# STM32G071 register map
File version: 2.1
CPU: CM0 r0p1, little endian, MPU, no FPU, 4 interrupt priority bits
Registers are 32-bit, read-write, reset 0x0 unless marked. A register's access mark holds for its fields unless they carry their own. Offsets are from the block's base; [hi:lo] are bit positions; {n}, {i} and the like mark numbered series; 'fields as' and 'values as' point back to an identical list.

## TIM15 — General purpose timers
Base 0x40014000
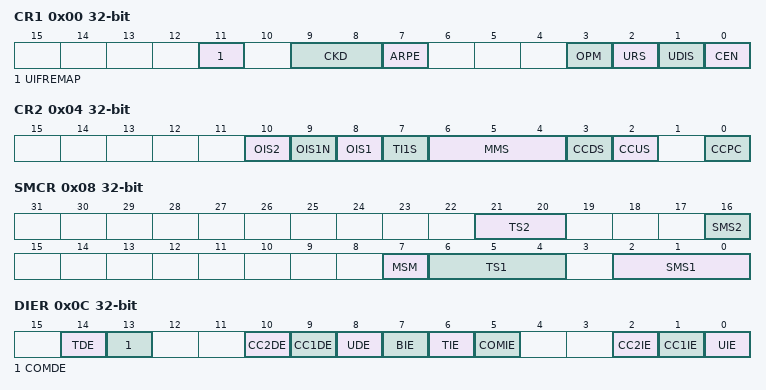
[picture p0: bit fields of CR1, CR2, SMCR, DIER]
0x00 CR1 — control register 1
  [11] UIFREMAP — UIF status bit remapping
    0=No remapping. UIF status bit is not copied to TIMx_CNT register bit 31.; 1=Remapping enabled. UIF status bit is copied to TIMx_CNT register bit 31.
  [9:8] CKD — Clock division This bitfield indicates the division ratio between the timer clock (CK_INT) frequency and the dead-time and sampling clock (tDTS) used by the dead-time generators and the digital filters (TIx)
    0=tDTS = tCK_INT; 1=tDTS = 2*tCK_INT; 2=tDTS = 4*tCK_INT; 3=Reserved, do not program this value
  [7] ARPE — Auto-reload preload enable
    0=TIMx_ARR register is not buffered; 1=TIMx_ARR register is buffered
  [3] OPM — One-pulse mode
    0=Counter is not stopped at update event; 1=Counter stops counting at the next update event (clearing the bit CEN)
  [2] URS — Update request source This bit is set and cleared by software to select the UEV event sources. Counter overflow/underflow Setting the UG bit Update generation through the slave mode controller
    0=Any of the following events generate an update interrupt if enabled. These events can be:; 1=Only counter overflow/underflow generates an update interrupt if enabled
  [1] UDIS — Update disable This bit is set and cleared by software to enable/disable UEV event generation. Counter overflow/underflow Setting the UG bit Update generation through the slave mode controller Buffered registers are then loaded with their preload values.
    0=UEV enabled. The Update (UEV) event is generated by one of the following events:; 1=UEV disabled. The Update event is not generated, shadow registers keep their value (ARR, PSC, CCRx). However the counter and the prescaler are reinitialized if the UG bit is set or if a hardware reset is received from the slave mode controller.
  [0] CEN — Counter enable Note: External clock and gated mode can work only if the CEN bit has been previously set by software. However trigger mode can set the CEN bit automatically by hardware.
    0=Counter disabled; 1=Counter enabled
0x04 CR2 — control register 2
  [10] OIS2 — Output idle state 2 (OC2 output) Note: This bit cannot be modified as long as LOCK level 1, 2 or 3 has been programmed (LOCK bits in the TIM15_BDTR register).
    0=OC2=0 when MOE=0; 1=OC2=1 when MOE=0
  [9] OIS1N — Output Idle state 1 (OC1N output) Note: This bit can not be modified as long as LOCK level 1, 2 or 3 has been programmed (LOCK bits in TIM15_BDTR register).
    0=OC1N=0 after a dead-time when MOE=0; 1=OC1N=1 after a dead-time when MOE=0
  [8] OIS1 — Output Idle state 1 (OC1 output) Note: This bit can not be modified as long as LOCK level 1, 2 or 3 has been programmed (LOCK bits in TIM15_BDTR register).
    0=OC1=0 (after a dead-time if OC1N is implemented) when MOE=0; 1=OC1=1 (after a dead-time if OC1N is implemented) when MOE=0
  [7] TI1S — TI1 selection
    0=The TIMx_CH1 pin is connected to TI1 input; 1=The TIMx_CH1, CH2 pins are connected to the TI1 input (XOR combination)
  [6:4] MMS — Master mode selection These bits allow to select the information to be sent in master mode to slave timers for synchronization (TRGO). The combination is as follows:
    0=Reset - the UG bit from the TIMx_EGR register is used as trigger output (TRGO). If the reset is generated by the trigger input (slave mode controller configured in reset mode) then the signal on TRGO is delayed compared to the actual reset.; 1=Enable - the Counter Enable signal CNT_EN is used as trigger output (TRGO). It is useful to start several timers at the same time or to control a window in which a slave timer is enable. The Counter Enable signal is generated by a logic AND between CEN control bit and the trigger input when configured in gated mode. When the Counter Enable signal is controlled by the trigger input, there is a delay on TRGO, except if the master/slave mode is selected (see the MSM bit description in TIMx_SMCR register).; 2=Update - The update event is selected as trigger output (TRGO). For instance a master timer can then be used as a prescaler for a slave timer.; 3=Compare Pulse - The trigger output send a positive pulse when the CC1IF flag is to be set (even if it was already high), as soon as a capture or a compare match occurred. (TRGO).; 4=Compare - OC1REFC signal is used as trigger output (TRGO); 5=Compare - OC2REFC signal is used as trigger output (TRGO)
  [3] CCDS — Capture/compare DMA selection
    0=CCx DMA request sent when CCx event occurs; 1=CCx DMA requests sent when update event occurs
  [2] CCUS — Capture/compare control update selection Note: This bit acts only on channels that have a complementary output.
    0=When capture/compare control bits are preloaded (CCPC=1), they are updated by setting the COMG bit only; 1=When capture/compare control bits are preloaded (CCPC=1), they are updated by setting the COMG bit or when an rising edge occurs on TRGI
  [0] CCPC — Capture/compare preloaded control Note: This bit acts only on channels that have a complementary output.
    0=CCxE, CCxNE and OCxM bits are not preloaded; 1=CCxE, CCxNE and OCxM bits are preloaded, after having been written, they are updated only when a commutation event (COM) occurs (COMG bit set or rising edge detected on TRGI, depending on the CCUS bit)
0x08 SMCR — slave mode control register
  [21:20] TS2 — Trigger selection This bit field selects the trigger input to be used to synchronize the counter. Other: Reserved See for more details on ITRx meaning for each Timer. Note: These bits must be changed only when they are not used (e.g. when SMS=000) to avoid wrong edge detections at the transition.
    {v}=Internal Trigger {v} (ITR{v}) (v=0..3); 4=TI1 Edge Detector (TI1F_ED); 5=Filtered Timer Input 1 (TI1FP1); 6=Filtered Timer Input 2 (TI2FP2)
  [16] SMS2 — Slave mode selection When external signals are selected the active edge of the trigger signal (TRGI) is linked to the polarity selected on the external input (see Input Control register and Control Register description. Other codes: reserved. Note: The gated mode must not be used if TI1F_ED is selected as the trigger input (TS='00100'). Indeed, TI1F_ED outputs 1 pulse for each transition on TI1F, whereas the gated mode checks the level of the trigger signal. Note: The clock of the slave peripherals (timer, ADC, ...) receiving the TRGO or the TRGO2 signals must be enabled prior to receive events from the master timer, and the clock frequency (prescaler) must not be changed on-the-fly while triggers are received from the master timer.
    0=Slave mode disabled - if CEN = '1' then the prescaler is clocked directly by the internal clock; 4=Reset Mode - Rising edge of the selected trigger input (TRGI) reinitializes the counter and generates an update of the registers; 5=Gated Mode - The counter clock is enabled when the trigger input (TRGI) is high. The counter stops (but is not reset) as soon as the trigger becomes low. Both start and stop of the counter are controlled.; 6=Trigger Mode - The counter starts at a rising edge of the trigger TRGI (but it is not reset). Only the start of the counter is controlled.; 7=External Clock Mode 1 - Rising edges of the selected trigger (TRGI) clock the counter; 8=Combined reset + trigger mode - Rising edge of the selected trigger input (TRGI) reinitializes the counter, generates an update of the registers and starts the counter
  [7] MSM — Master/slave mode
    0=No action; 1=The effect of an event on the trigger input (TRGI) is delayed to allow a perfect synchronization between the current timer and its slaves (through TRGO). It is useful if we want to synchronize several timers on a single external event.
  [6:4] TS1 — Trigger selection This bit field selects the trigger input to be used to synchronize the counter. Other: Reserved See for more details on ITRx meaning for each Timer. Note: These bits must be changed only when they are not used (e.g. when SMS=000) to avoid wrong edge detections at the transition.
    values as TS2
  [2:0] SMS1 — Slave mode selection When external signals are selected the active edge of the trigger signal (TRGI) is linked to the polarity selected on the external input (see Input Control register and Control Register description. Other codes: reserved. Note: The gated mode must not be used if TI1F_ED is selected as the trigger input (TS='00100'). Indeed, TI1F_ED outputs 1 pulse for each transition on TI1F, whereas the gated mode checks the level of the trigger signal. Note: The clock of the slave peripherals (timer, ADC, ...) receiving the TRGO or the TRGO2 signals must be enabled prior to receive events from the master timer, and the clock frequency (prescaler) must not be changed on-the-fly while triggers are received from the master timer.
    values as SMS2
0x0C DIER — DMA/Interrupt enable register
  [14] TDE — Trigger DMA request enable
    0=Trigger DMA request disabled; 1=Trigger DMA request enabled
  [13] COMDE — COM DMA request enable
    0=COM DMA request disabled; 1=COM DMA request enabled
  [10] CC2DE — Capture/Compare 2 DMA request enable
    0=CC2 DMA request disabled; 1=CC2 DMA request enabled
  [9] CC1DE — Capture/Compare 1 DMA request enable
    0=CC1 DMA request disabled; 1=CC1 DMA request enabled
  [8] UDE — Update DMA request enable
    0=Update DMA request disabled; 1=Update DMA request enabled
  [7] BIE — Break interrupt enable
    0=Break interrupt disabled; 1=Break interrupt enabled
  [6] TIE — Trigger interrupt enable
    0=Trigger interrupt disabled; 1=Trigger interrupt enabled
  [5] COMIE — COM interrupt enable
    0=COM interrupt disabled; 1=COM interrupt enabled
  [2] CC2IE — Capture/Compare 2 interrupt enable
    0=CC2 interrupt disabled; 1=CC2 interrupt enabled
  [1] CC1IE — Capture/Compare 1 interrupt enable
    0=CC1 interrupt disabled; 1=CC1 interrupt enabled
  [0] UIE — Update interrupt enable
    0=Update interrupt disabled; 1=Update interrupt enabled
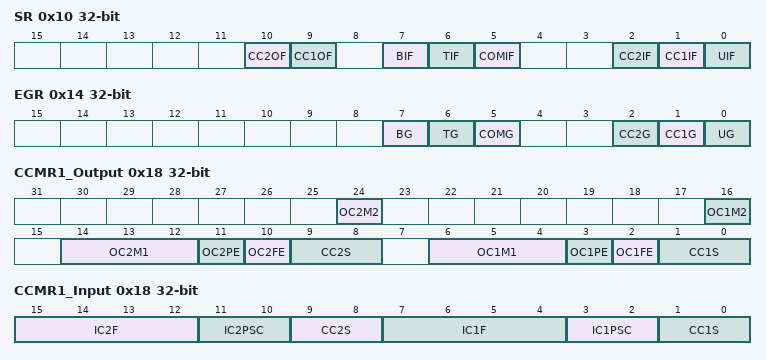
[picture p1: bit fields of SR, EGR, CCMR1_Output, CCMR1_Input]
0x10 SR — status register
  [10] CC2OF — Capture/Compare 2 overcapture flag Refer to CC1OF description
  [9] CC1OF — Capture/Compare 1 overcapture flag This flag is set by hardware only when the corresponding channel is configured in input capture mode. It is cleared by software by writing it to '0'.
    0=No overcapture has been detected; 1=The counter value has been captured in TIMx_CCR1 register while CC1IF flag was already set
  [7] BIF — Break interrupt flag This flag is set by hardware as soon as the break input goes active. It can be cleared by software if the break input is not active.
    0=No break event occurred; 1=An active level has been detected on the break input
  [6] TIF — Trigger interrupt flag This flag is set by hardware on the TRG trigger event (active edge detected on TRGI input when the slave mode controller is enabled in all modes but gated mode, both edges in case gated mode is selected). It is set when the counter starts or stops when gated mode is selected. It is cleared by software.
    0=No trigger event occurred; 1=Trigger interrupt pending
  [5] COMIF — COM interrupt flag This flag is set by hardware on a COM event (once the capture/compare control bits -CCxE, CCxNE, OCxM- have been updated). It is cleared by software.
    0=No COM event occurred; 1=COM interrupt pending
  [2] CC2IF — Capture/Compare 2 interrupt flag refer to CC1IF description
  [1] CC1IF — Capture/Compare 1 interrupt flag This flag is set by hardware. It is cleared by software (input capture or output compare mode) or by reading the TIMx_CCR1 register (input capture mode only). If channel CC1 is configured as output: this flag is set when the content of the counter TIMx_CNT matches the content of the TIMx_CCR1 register. When the content of TIMx_CCR1 is greater than the content of TIMx_ARR, the CC1IF bit goes high on the counter overflow (in up-counting and up/down-counting modes) or underflow (in down-counting mode). There are 3 possible options for flag setting in center-aligned mode, refer to the CMS bits in the TIMx_CR1 register for the full description. If channel CC1 is configured as input: this bit is set when counter value has been captured in TIMx_CCR1 register (an edge has been detected on IC1, as per the edge sensitivity defined with the CC1P and CC1NP bits setting, in TIMx_CCER).
    0=No compare match / No input capture occurred; 1=A compare match or an input capture occurred
  [0] UIF — Update interrupt flag This bit is set by hardware on an update event. It is cleared by software. At overflow regarding the repetition counter value (update if repetition counter = 0) and if the UDIS=0 in the TIMx_CR1 register. When CNT is reinitialized by software using the UG bit in TIMx_EGR register, if URS=0 and UDIS=0 in the TIMx_CR1 register. When CNT is reinitialized by a trigger event (refer to control register (TIM15_SMCR)), if URS=0 and UDIS=0 in the TIMx_CR1 register.
    0=No update occurred; 1=Update interrupt pending. This bit is set by hardware when the registers are updated:
0x14 EGR wo — event generation register
  [7] BG — Break generation This bit is set by software in order to generate an event, it is automatically cleared by hardware.
    0=No action; 1=A break event is generated. MOE bit is cleared and BIF flag is set. Related interrupt or DMA transfer can occur if enabled.
  [6] TG — Trigger generation This bit is set by software in order to generate an event, it is automatically cleared by hardware.
    0=No action; 1=The TIF flag is set in TIMx_SR register. Related interrupt or DMA transfer can occur if enabled
  [5] COMG rw — Capture/Compare control update generation This bit can be set by software, it is automatically cleared by hardware. Note: This bit acts only on channels that have a complementary output.
    0=No action; 1=When the CCPC bit is set, it is possible to update the CCxE, CCxNE and OCxM bits
  [2] CC2G — Capture/Compare 2 generation Refer to CC1G description
  [1] CC1G — Capture/Compare 1 generation This bit is set by software in order to generate an event, it is automatically cleared by hardware. If channel CC1 is configured as output: CC1IF flag is set, Corresponding interrupt or DMA request is sent if enabled. If channel CC1 is configured as input: The current value of the counter is captured in TIMx_CCR1 register. The CC1IF flag is set, the corresponding interrupt or DMA request is sent if enabled. The CC1OF flag is set if the CC1IF flag was already high.
    0=No action; 1=A capture/compare event is generated on channel 1:
  [0] UG — Update generation This bit can be set by software, it is automatically cleared by hardware.
    0=No action; 1=Reinitialize the counter and generates an update of the registers. Note that the prescaler counter is cleared too (anyway the prescaler ratio is not affected).
0x18 CCMR1_Output — capture/compare mode register (output mode)
  [24] OC2M2 — Output Compare 2 mode
  [16] OC1M2 — Output Compare 1 mode These bits define the behavior of the output reference signal OC1REF from which OC1 and OC1N are derived. OC1REF is active high whereas OC1 and OC1N active level depends on CC1P and CC1NP bits. Note: These bits can not be modified as long as LOCK level 3 has been programmed (LOCK bits in TIMx_BDTR register) and CC1S='00' (the channel is configured in output). In PWM mode, the OCREF level changes only when the result of the comparison changes or when the output compare mode switches from "frozen" mode to "PWM" mode. On channels that have a complementary output, this bit field is preloaded. If the CCPC bit is set in the TIMx_CR2 register then the OC1M active bits take the new value from the preloaded bits only when a COM event is generated. The OC1M[3] bit is not contiguous, located in bit 16.
    0=Frozen - The comparison between the output compare register TIMx_CCR1 and the counter TIMx_CNT has no effect on the outputs; 1=Set channel 1 to active level on match. OC1REF signal is forced high when the counter TIMx_CNT matches the capture/compare register 1 (TIMx_CCR1).; 2=Set channel 1 to inactive level on match. OC1REF signal is forced low when the counter TIMx_CNT matches the capture/compare register 1 (TIMx_CCR1).; 3=Toggle - OC1REF toggles when TIMx_CNT=TIMx_CCR1; 4=Force inactive level - OC1REF is forced low; 5=Force active level - OC1REF is forced high; 6=PWM mode 1 - Channel 1 is active as long as TIMx_CNT<TIMx_CCR1 else inactive; 7=PWM mode 2 - Channel 1 is inactive as long as TIMx_CNT<TIMx_CCR1 else active; 8=Retrigerrable OPM mode 1 - In up-counting mode, the channel is active until a trigger event is detected (on TRGI signal). Then, a comparison is performed as in PWM mode 1 and the channels becomes active again at the next update. In down-counting mode, the channel is inactive until a trigger event is detected (on TRGI signal). Then, a comparison is performed as in PWM mode 1 and the channels becomes inactive again at the next update.; 9=Retrigerrable OPM mode 2 - In up-counting mode, the channel is inactive until a trigger event is detected (on TRGI signal). Then, a comparison is performed as in PWM mode 2 and the channels becomes inactive again at the next update. In down-counting mode, the channel is active until a trigger event is detected (on TRGI signal). Then, a comparison is performed as in PWM mode 1 and the channels becomes active again at the next update.; 12=Combined PWM mode 1 - OC1REF has the same behavior as in PWM mode 1. OC1REFC is the logical OR between OC1REF and OC2REF.; 13=Combined PWM mode 2 - OC1REF has the same behavior as in PWM mode 2. OC1REFC is the logical AND between OC1REF and OC2REF.
  [14:12] OC2M1 — Output Compare 2 mode
  [11] OC2PE — Output Compare 2 preload enable
  [10] OC2FE — Output Compare 2 fast enable
  [9:8] CC2S — Capture/Compare 2 selection This bit-field defines the direction of the channel (input/output) as well as the used input. Note: CC2S bits are writable only when the channel is OFF (CC2E = '0' in TIMx_CCER).
    0=CC2 channel is configured as output; 1=CC2 channel is configured as input, IC2 is mapped on TI2; 2=CC2 channel is configured as input, IC2 is mapped on TI1; 3=CC2 channel is configured as input, IC2 is mapped on TRC. This mode is working only if an internal trigger input is selected through the TS bit (TIMx_SMCR register)
  [6:4] OC1M1 — Output Compare 1 mode These bits define the behavior of the output reference signal OC1REF from which OC1 and OC1N are derived. OC1REF is active high whereas OC1 and OC1N active level depends on CC1P and CC1NP bits. Note: These bits can not be modified as long as LOCK level 3 has been programmed (LOCK bits in TIMx_BDTR register) and CC1S='00' (the channel is configured in output). In PWM mode, the OCREF level changes only when the result of the comparison changes or when the output compare mode switches from "frozen" mode to "PWM" mode. On channels that have a complementary output, this bit field is preloaded. If the CCPC bit is set in the TIMx_CR2 register then the OC1M active bits take the new value from the preloaded bits only when a COM event is generated. The OC1M[3] bit is not contiguous, located in bit 16.
    values as OC1M2
  [3] OC1PE — Output Compare 1 preload enable Note: These bits can not be modified as long as LOCK level 3 has been programmed (LOCK bits in TIMx_BDTR register) and CC1S='00' (the channel is configured in output). The PWM mode can be used without validating the preload register only in one pulse mode (OPM bit set in TIMx_CR1 register). Else the behavior is not guaranteed.
    0=Preload register on TIMx_CCR1 disabled. TIMx_CCR1 can be written at anytime, the new value is taken in account immediately.; 1=Preload register on TIMx_CCR1 enabled. Read/Write operations access the preload register. TIMx_CCR1 preload value is loaded in the active register at each update event.
  [2] OC1FE — Output Compare 1 fast enable This bit decreases the latency between a trigger event and a transition on the timer output. It must be used in one-pulse mode (OPM bit set in TIMx_CR1 register), to have the output pulse starting as soon as possible after the starting trigger.
    0=CC1 behaves normally depending on counter and CCR1 values even when the trigger is ON. The minimum delay to activate CC1 output when an edge occurs on the trigger input is 5 clock cycles.; 1=An active edge on the trigger input acts like a compare match on CC1 output. Then, OC is set to the compare level independently of the result of the comparison. Delay to sample the trigger input and to activate CC1 output is reduced to 3 clock cycles. OCFE acts only if the channel is configured in PWM1 or PWM2 mode.
  [1:0] CC1S — Capture/Compare 1 selection This bit-field defines the direction of the channel (input/output) as well as the used input. Note: CC1S bits are writable only when the channel is OFF (CC1E = '0' in TIMx_CCER).
    0=CC1 channel is configured as output; 1=CC1 channel is configured as input, IC1 is mapped on TI1; 2=CC1 channel is configured as input, IC1 is mapped on TI2; 3=CC1 channel is configured as input, IC1 is mapped on TRC. This mode is working only if an internal trigger input is selected through TS bit (TIMx_SMCR register)
0x18 CCMR1_Input (alternate view of CCMR1_Output) — capture/compare mode register 1 (input mode)
  [15:12] IC2F — Input capture 2 filter
  [11:10] IC2PSC — Input capture 2 prescaler
  [9:8] CC2S — Capture/Compare 2 selection This bit-field defines the direction of the channel (input/output) as well as the used input. Note: CC2S bits are writable only when the channel is OFF (CC2E = '0' in TIMx_CCER).
    0=CC2 channel is configured as output; 1=CC2 channel is configured as input, IC2 is mapped on TI2; 2=CC2 channel is configured as input, IC2 is mapped on TI1; 3=CC2 channel is configured as input, IC2 is mapped on TRC. This mode is working only if an internal trigger input is selected through TS bit (TIMx_SMCR register)
  [7:4] IC1F — Input capture 1 filter This bit-field defines the frequency used to sample TI1 input and the length of the digital filter applied to TI1. The digital filter is made of an event counter in which N consecutive events are needed to validate a transition on the output:
    0=No filter, sampling is done at fDTS; 1=fSAMPLING=fCK_INT, N=2; 2=fSAMPLING=fCK_INT, N=4; 3=fSAMPLING=fCK_INT, N=8; 4=fSAMPLING=fDTS/2, N=6; 5=fSAMPLING=fDTS/2, N=8; 6=fSAMPLING=fDTS/4, N=6; 7=fSAMPLING=fDTS/4, N=8; 8=fSAMPLING=fDTS/8, N=6; 9=fSAMPLING=fDTS/8, N=8; 10=fSAMPLING=fDTS/16, N=5; 11=fSAMPLING=fDTS/16, N=6; 12=fSAMPLING=fDTS/16, N=8; 13=fSAMPLING=fDTS/32, N=5; 14=fSAMPLING=fDTS/32, N=6; 15=fSAMPLING=fDTS/32, N=8
  [3:2] IC1PSC — Input capture 1 prescaler This bit-field defines the ratio of the prescaler acting on CC1 input (IC1). The prescaler is reset as soon as CC1E='0' (TIMx_CCER register).
    0=no prescaler, capture is done each time an edge is detected on the capture input; 1=capture is done once every 2 events; 2=capture is done once every 4 events; 3=capture is done once every 8 events
  [1:0] CC1S — Capture/Compare 1 Selection This bit-field defines the direction of the channel (input/output) as well as the used input. Note: CC1S bits are writable only when the channel is OFF (CC1E = '0' in TIMx_CCER).
    values as CCMR1_Output.CC1S
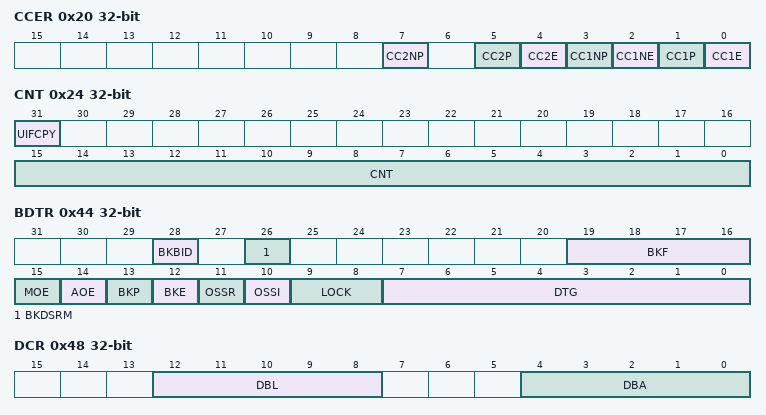
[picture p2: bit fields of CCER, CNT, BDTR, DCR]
0x20 CCER — capture/compare enable register
  [7] CC2NP — Capture/Compare 2 complementary output polarity Refer to CC1NP description
  [5] CC2P — Capture/Compare 2 output polarity Refer to CC1P description
  [4] CC2E — Capture/Compare 2 output enable Refer to CC1E description
  [3] CC1NP — Capture/Compare 1 complementary output polarity CC1 channel configured as output: CC1 channel configured as input: This bit is used in conjunction with CC1P to define the polarity of TI1FP1 and TI2FP1. Refer to CC1P description. Note: This bit is not writable as soon as LOCK level 2 or 3 has been programmed (LOCK bits in TIMx_BDTR register) and CC1S="00" (the channel is configured in output). On channels that have a complementary output, this bit is preloaded. If the CCPC bit is set in the TIMx_CR2 register then the CC1NP active bit takes the new value from the preloaded bit only when a Commutation event is generated.
    0=OC1N active high; 1=OC1N active low
  [2] CC1NE — Capture/Compare 1 complementary output enable
    0=Off - OC1N is not active. OC1N level is then function of MOE, OSSI, OSSR, OIS1, OIS1N and CC1E bits.; 1=On - OC1N signal is output on the corresponding output pin depending on MOE, OSSI, OSSR, OIS1, OIS1N and CC1E bits
  [1] CC1P — Capture/Compare 1 output polarity When CC1 channel is configured as input, both CC1NP/CC1P bits select the active polarity of TI1FP1 and TI2FP1 for trigger or capture operations. CC1NP=0, CC1P=0: non-inverted/rising edge. The circuit is sensitive to TIxFP1 rising edge (capture or trigger operations in reset, external clock or trigger mode), TIxFP1 is not inverted (trigger operation in gated mode or encoder mode). CC1NP=0, CC1P=1: inverted/falling edge. The circuit is sensitive to TIxFP1 falling edge (capture or trigger operations in reset, external clock or trigger mode), TIxFP1 is inverted (trigger operation in gated mode or encoder mode). CC1NP=1, CC1P=1: non-inverted/both edges/ The circuit is sensitive to both TIxFP1 rising and falling edges (capture or trigger operations in reset, external clock or trigger mode), TIxFP1is not inverted (trigger operation in gated mode). This configuration must not be used in encoder mode. CC1NP=1, CC1P=0: this configuration is reserved, it must not be used. Note: This bit is not writable as soon as LOCK level 2 or 3 has been programmed (LOCK bits in TIMx_BDTR register). On channels that have a complementary output, this bit is preloaded. If the CCPC bit is set in the TIMx_CR2 register then the CC1P active bit takes the new value from the preloaded bit only when a Commutation event is generated.
    0=OC1 active high (output mode) / Edge sensitivity selection (input mode, see below); 1=OC1 active low (output mode) / Edge sensitivity selection (input mode, see below)
  [0] CC1E — Capture/Compare 1 output enable When CC1 channel is configured as output, the OC1 level depends on MOE, OSSI, OSSR, OIS1, OIS1N and CC1NE bits, regardless of the CC1E bits state. Refer to for details.
    0=Capture mode disabled / OC1 is not active (see below); 1=Capture mode enabled / OC1 signal is output on the corresponding output pin
0x24 CNT access per field — counter
  [31] UIFCPY ro — UIF Copy
  [15:0] CNT rw — counter value
0x28 PSC — prescaler
  [15:0] PSC — Prescaler value
0x2C ARR reset 0xFFFF — auto-reload register
  [15:0] ARR — Auto-reload value
0x30 RCR — repetition counter register
  [7:0] REP — Repetition counter value
0x34 CCR1 — capture/compare register 1
  [15:0] CCR1 — Capture/Compare 1 value
0x38 CCR2 — capture/compare register 2
  [15:0] CCR2 — Capture/Compare 2 value
0x44 BDTR — break and dead-time register
  [28] BKBID — Break Bidirectional In the bidirectional mode (BKBID bit set to 1), the break input is configured both in input mode and in open drain output mode. Any active break event asserts a low logic level on the Break input to indicate an internal break event to external devices. Note: This bit cannot be modified as long as LOCK level 1 has been programmed (LOCK bits in TIMx_BDTR register). Note: Any write operation to this bit takes a delay of 1 APB clock cycle to become effective.
    0=Break input BRK in input mode; 1=Break input BRK in bidirectional mode
  [26] BKDSRM — Break Disarm This bit is cleared by hardware when no break source is active. The BKDSRM bit must be set by software to release the bidirectional output control (open-drain output in Hi-Z state) and then be polled it until it is reset by hardware, indicating that the fault condition has disappeared. Note: Any write operation to this bit takes a delay of 1 APB clock cycle to become effective.
    0=Break input BRK is armed; 1=Break input BRK is disarmed
  [19:16] BKF — Break filter This bit-field defines the frequency used to sample the BRK input signal and the length of the digital filter applied to BRK. The digital filter is made of an event counter in which N events are needed to validate a transition on the output: Note: This bit cannot be modified when LOCK level 1 has been programmed (LOCK bits in TIMx_BDTR register).
    0=No filter, BRK acts asynchronously; 1=fSAMPLING=fCK_INT, N=2; 2=fSAMPLING=fCK_INT, N=4; 3=fSAMPLING=fCK_INT, N=8; 4=fSAMPLING=fDTS/2, N=6; 5=fSAMPLING=fDTS/2, N=8; 6=fSAMPLING=fDTS/4, N=6; 7=fSAMPLING=fDTS/4, N=8; 8=fSAMPLING=fDTS/8, N=6; 9=fSAMPLING=fDTS/8, N=8; 10=fSAMPLING=fDTS/16, N=5; 11=fSAMPLING=fDTS/16, N=6; 12=fSAMPLING=fDTS/16, N=8; 13=fSAMPLING=fDTS/32, N=5; 14=fSAMPLING=fDTS/32, N=6; 15=fSAMPLING=fDTS/32, N=8
  [15] MOE — Main output enable This bit is cleared asynchronously by hardware as soon as the break input is active. It is set by software or automatically depending on the AOE bit. It is acting only on the channels which are configured in output. See OC/OCN enable description for more details (enable register (TIM15_CCER) on page 818).
    0=OC and OCN outputs are disabled or forced to idle state depending on the OSSI bit; 1=OC and OCN outputs are enabled if their respective enable bits are set (CCxE, CCxNE in TIMx_CCER register)
  [14] AOE — Automatic output enable Note: This bit can not be modified as long as LOCK level 1 has been programmed (LOCK bits in TIMx_BDTR register).
    0=MOE can be set only by software; 1=MOE can be set by software or automatically at the next update event (if the break input is not be active)
  [13] BKP — Break polarity Note: This bit can not be modified as long as LOCK level 1 has been programmed (LOCK bits in TIMx_BDTR register). Any write operation to this bit takes a delay of 1 APB clock cycle to become effective.
    0=Break input BRK is active low; 1=Break input BRK is active high
  [12] BKE — Break enable 1; Break inputs (BRK and CCS clock failure event) enabled This bit cannot be modified when LOCK level 1 has been programmed (LOCK bits in TIMx_BDTR register). Note: Any write operation to this bit takes a delay of 1 APB clock cycle to become effective.
    0=Break inputs (BRK and CCS clock failure event) disabled
  [11] OSSR — Off-state selection for Run mode This bit is used when MOE=1 on channels that have a complementary output which are configured as outputs. OSSR is not implemented if no complementary output is implemented in the timer. See OC/OCN enable description for more details (enable register (TIM15_CCER) on page 818). Note: This bit can not be modified as soon as the LOCK level 2 has been programmed (LOCK bits in TIMx_BDTR register).
    0=When inactive, OC/OCN outputs are disabled (the timer releases the output control which is taken over by the AFIO logic, which forces a Hi-Z state); 1=When inactive, OC/OCN outputs are enabled with their inactive level as soon as CCxE=1 or CCxNE=1 (the output is still controlled by the timer)
  [10] OSSI — Off-state selection for Idle mode This bit is used when MOE=0 on channels configured as outputs. See OC/OCN enable description for more details (enable register (TIM15_CCER) on page 818). Note: This bit can not be modified as soon as the LOCK level 2 has been programmed (LOCK bits in TIMx_BDTR register).
    0=When inactive, OC/OCN outputs are disabled (OC/OCN enable output signal=0); 1=When inactive, OC/OCN outputs are forced first with their idle level as soon as CCxE=1 or CCxNE=1. OC/OCN enable output signal=1)
  [9:8] LOCK — Lock configuration These bits offer a write protection against software errors. Note: The LOCK bits can be written only once after the reset. Once the TIMx_BDTR register has been written, their content is frozen until the next reset.
    0=LOCK OFF - No bit is write protected; 1=LOCK Level 1 = DTG bits in TIMx_BDTR register, OISx and OISxN bits in TIMx_CR2 register and BKE/BKP/AOE bits in TIMx_BDTR register can no longer be written; 2=LOCK Level 2 = LOCK Level 1 + CC Polarity bits (CCxP/CCxNP bits in TIMx_CCER register, as long as the related channel is configured in output through the CCxS bits) as well as OSSR and OSSI bits can no longer be written; 3=LOCK Level 3 = LOCK Level 2 + CC Control bits (OCxM and OCxPE bits in TIMx_CCMRx registers, as long as the related channel is configured in output through the CCxS bits) can no longer be written
  [7:0] DTG — Dead-time generator setup This bit-field defines the duration of the dead-time inserted between the complementary outputs. DT correspond to this duration. DTG[7:5]=0xx => DT=DTG[7:0]x tdtg with tdtg=tDTS DTG[7:5]=10x => DT=(64+DTG[5:0])xtdtg with Tdtg=2xtDTS DTG[7:5]=110 => DT=(32+DTG[4:0])xtdtg with Tdtg=8xtDTS DTG[7:5]=111 => DT=(32+DTG[4:0])xtdtg with Tdtg=16xtDTS Example if TDTS=125ns (8MHz), dead-time possible values are: 0 to 15875 ns by 125 ns steps, 16 us to 31750 ns by 250 ns steps, 32 us to 63 us by 1 us steps, 64 us to 126 us by 2 us steps Note: This bit-field can not be modified as long as LOCK level 1, 2 or 3 has been programmed (LOCK bits in TIMx_BDTR register).
0x48 DCR — DMA control register
  [12:8] DBL — DMA burst length This 5-bit field defines the length of DMA transfers (the timer recognizes a burst transfer when a read or a write access is done to the TIMx_DMAR address). ...
    0=1 transfer,; 1=2 transfers,; 2=3 transfers,; 17=18 transfers
  [4:0] DBA — DMA base address This 5-bit field defines the base-address for DMA transfers (when read/write access are done through the TIMx_DMAR address). DBA is defined as an offset starting from the address of the TIMx_CR1 register. Example: ...
    0=TIMx_CR1,; 1=TIMx_CR2,; 2=TIMx_SMCR,
0x4C DMAR — DMA address for full transfer
  [15:0] DMAB — DMA register for burst accesses
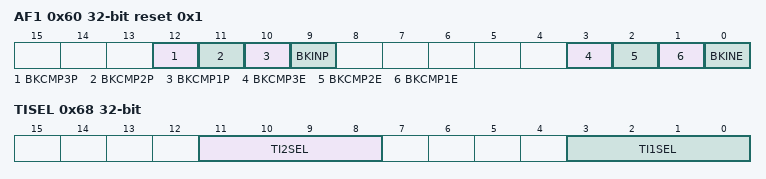
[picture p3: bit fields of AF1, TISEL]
0x60 AF1 reset 0x1 — TIM15 alternate register 1
  [12] BKCMP3P — BRK COMP3 input polarity This bit selects the COMP3 input sensitivity. It must be programmed together with the BKP polarity bit. Note: This bit can not be modified as long as LOCK level 1 has been programmed (LOCK bits in TIMx_BDTR register).
    0=COMP3 input is active low; 1=COMP3 input is active high
  [11] BKCMP2P — BRK COMP2 input polarity This bit selects the COMP2 input sensitivity. It must be programmed together with the BKP polarity bit. Note: This bit can not be modified as long as LOCK level 1 has been programmed (LOCK bits in TIMx_BDTR register).
    0=COMP2 input is active low; 1=COMP2 input is active high
  [10] BKCMP1P — BRK COMP1 input polarity This bit selects the COMP1 input sensitivity. It must be programmed together with the BKP polarity bit. Note: This bit can not be modified as long as LOCK level 1 has been programmed (LOCK bits in TIMx_BDTR register).
    0=COMP1 input is active low; 1=COMP1 input is active high
  [9] BKINP — BRK BKIN input polarity This bit selects the BKIN alternate function input sensitivity. It must be programmed together with the BKP polarity bit. Note: This bit can not be modified as long as LOCK level 1 has been programmed (LOCK bits in TIMx_BDTR register).
    0=BKIN input is active low; 1=BKIN input is active high
  [3] BKCMP3E — BRK COMP3 enable This bit enables the COMP3 for the timer's BRK input. COMP3 output is 'ORed' with the other BRK sources. Note: This bit can not be modified as long as LOCK level 1 has been programmed (LOCK bits in TIMx_BDTR register).
    0=COMP3 input disabled; 1=COMP3 input enabled
  [2] BKCMP2E — BRK COMP2 enable This bit enables the COMP2 for the timer's BRK input. COMP2 output is 'ORed' with the other BRK sources. Note: This bit can not be modified as long as LOCK level 1 has been programmed (LOCK bits in TIMx_BDTR register).
    0=COMP2 input disabled; 1=COMP2 input enabled
  [1] BKCMP1E — BRK COMP1 enable This bit enables the COMP1 for the timer's BRK input. COMP1 output is 'ORed' with the other BRK sources. Note: This bit can not be modified as long as LOCK level 1 has been programmed (LOCK bits in TIMx_BDTR register).
    0=COMP1 input disabled; 1=COMP1 input enabled
  [0] BKINE — BRK BKIN input enable This bit enables the BKIN alternate function input for the timer's BRK input. BKIN input is 'ORed' with the other BRK sources. Note: This bit can not be modified as long as LOCK level 1 has been programmed (LOCK bits in TIMx_BDTR register).
    0=BKIN input disabled; 1=BKIN input enabled
0x68 TISEL — input selection register
  [11:8] TI2SEL — selects TI2[0] to TI2[15] input Others: Reserved
    0=TIM15_CH2 input; 1=TIM2_IC2; 2=TIM3_IC2
  [3:0] TI1SEL — selects TI1[0] to TI1[15] input Others: Reserved
    0=TIM15_CH1 input; 1=TIM2_IC1; 2=TIM3_IC1
